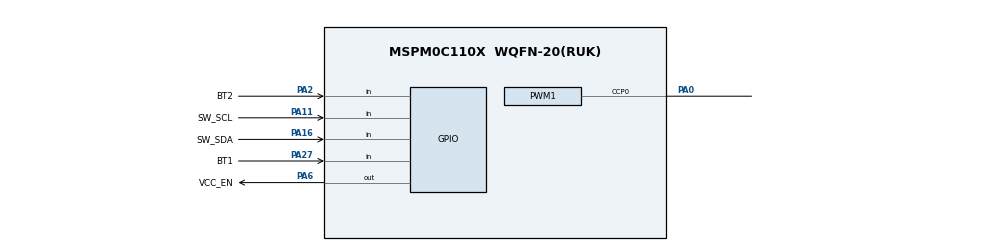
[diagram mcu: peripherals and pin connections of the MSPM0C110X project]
/**
 * @cliArgs --device "MSPM0C110X" --part "Default" --package "WQFN-20(RUK)" --product "mspm0_sdk@2.11.00.07"
 * @versions {"tool":"1.26.2+4477"}
 */
scripting.excludeFromBuild("device_linker.cmd");

/**
 * Import the modules used in this configuration.
 */
const ADC12  = scripting.addModule("/ti/driverlib/ADC12", {}, false);
const ADC121 = ADC12.addInstance();
const GPIO   = scripting.addModule("/ti/driverlib/GPIO", {}, false);
const GPIO1  = GPIO.addInstance();
const GPIO2  = GPIO.addInstance();
const GPIO3  = GPIO.addInstance();
const PWM    = scripting.addModule("/ti/driverlib/PWM", {}, false);
const PWM1   = PWM.addInstance();
const VREF   = scripting.addModule("/ti/driverlib/VREF");
const WWDT   = scripting.addModule("/ti/driverlib/WWDT", {}, false);
const WWDT1  = WWDT.addInstance();

/**
 * Write custom configuration values to the imported modules.
 */
ADC121.$name          = "ADC12_0";
ADC121.adcMem0vref    = "VREF";
ADC121.adcMem0chansel = "DL_ADC12_INPUT_CHAN_15";

const Board = scripting.addModule("/ti/driverlib/Board", {}, false);

GPIO1.$name                         = "OUTPUT_PINS";
GPIO1.associatedPins[0].$name       = "VCC_EN";
GPIO1.associatedPins[0].pin.$assign = "PA6";

GPIO2.$name                              = "BUTTONS";
GPIO2.associatedPins.create(2);
GPIO2.associatedPins[0].$name            = "BT1";
GPIO2.associatedPins[0].direction        = "INPUT";
GPIO2.associatedPins[0].internalResistor = "PULL_UP";
GPIO2.associatedPins[0].pin.$assign      = "PA27";
GPIO2.associatedPins[1].$name            = "BT2";
GPIO2.associatedPins[1].direction        = "INPUT";
GPIO2.associatedPins[1].internalResistor = "PULL_UP";
GPIO2.associatedPins[1].pin.$assign      = "PA2";

GPIO3.$name                         = "SW_I2C";
GPIO3.associatedPins.create(2);
GPIO3.associatedPins[0].$name       = "SW_SDA";
GPIO3.associatedPins[0].direction   = "INPUT";
GPIO3.associatedPins[0].pin.$assign = "PA16";
GPIO3.associatedPins[1].$name       = "SW_SCL";
GPIO3.associatedPins[1].direction   = "INPUT";
GPIO3.associatedPins[1].pin.$assign = "PA11";

PWM1.$name                      = "PWM_0";
PWM1.ccIndex                    = [0];
PWM1.timerCount                 = 2400;
PWM1.PWM_CHANNEL_0.$name        = "ti_driverlib_pwm_PWMTimerCC0";
PWM1.ccp0PinConfig.$name        = "ti_driverlib_gpio_GPIOPinGeneric0";
PWM1.peripheral.$assign         = "TIMG8";
PWM1.peripheral.ccp0Pin.$assign = "PA0";

const SYSCTL = scripting.addModule("/ti/driverlib/SYSCTL", {}, false);

WWDT1.$name = "WWDT0";

/**
 * Pinmux solution for unlocked pins/peripherals. This ensures that minor changes to the automatic solver in a future
 * version of the tool will not impact the pinmux you originally saw.  These lines can be completely deleted in order to
 * re-solve from scratch.
 */
ADC121.peripheral.$suggestSolution         = "ADC0";
Board.peripheral.$suggestSolution          = "DEBUGSS";
Board.peripheral.swclkPin.$suggestSolution = "PA20";
Board.peripheral.swdioPin.$suggestSolution = "PA19";
SYSCTL.peripheral.$suggestSolution         = "SYSCTL";
WWDT1.peripheral.$suggestSolution          = "WWDT0";
